# YTM32B1LE1 register map
Vendor: YTMicro; File version: 1.0
CPU: CM0PLUS r0p1, little endian, MPU, FPU, 2 interrupt priority bits
Registers are 32-bit, read-write, reset 0x0 unless marked. A register's access mark holds for its fields unless they carry their own. Offsets are from the block's base; [hi:lo] are bit positions.

## lpTMR0 — Low Power Timer
Base 0x40040000; register names take the prefix lpTMR0_
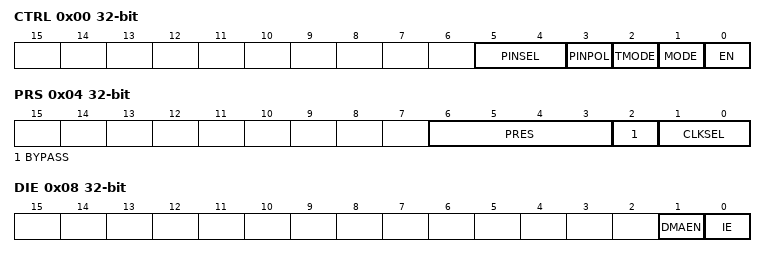
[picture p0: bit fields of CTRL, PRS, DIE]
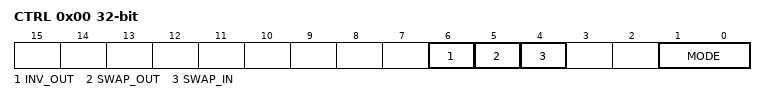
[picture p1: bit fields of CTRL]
0x00 CTRL
  [5:4] PINSEL — Configures the input source to be used in Pulse Counter mode. PINSEL must be altered only when the lpTMR is disabled.
    0=Pulse counter input 0 is selected. (It's from TMU); 2=Pulse counter input 2 is selected. (It's from lpTMR_ALT2 pad); 3=Pulse counter input 3 is selected. (It's from lpTMR_ALT3 pad)
  [3] PINPOL — Configures the polarity of the input source in Pulse Counter mode. PINPOL must be changed only when the lpTMR is disabled.
    0=Pulse Counter input source is active-high, and the CNT will increment on the rising-edge; 1=Pulse Counter input source is active-low, and the CNT will increment on the falling-edge
  [2] TMODE — When clear, TMODE configures the CNT to reset whenever CCF is set. When set, TMODE configures the CNT to reset on overflow. TMODE must be altered only when the lpTMR is disabled.
    0=CNT is reset whenever CCF is set; 1=CNT is reset on overflow
  [1] MODE — Configures the mode of the lpTMR. MODE must be altered only when the lpTMR is disabled.
    0=Time Counter mode; 1=Pulse Counter mode
  [0] EN — When EN is clear, it resets the lpTMR internal logic, including the CNT and CCF. When EN is set, the lpTMR is enabled. While writing 1 to this field, CTRL[5:1] must not be altered.
    0=lpTMR is disabled and internal logic is reset; 1=lpTMR is enabled
0x04 PRS
  [6:3] PRES — Configures the size of the Prescaler in Time Counter mode or width of the glitch filter in Pulse Counter mode. The width of the glitch filter can vary by 1 cycle due to synchronization of the pulse counter input. ewline Prescaler divides the prescaler clock by 2^(PRES+1) and glitch filter recognizes change on input pin after 2^PRES rising clock edges. ewline PRESCALE must be altered only when the lpTMR is disabled.
  [2] BYPASS — When BYPASS is set, the selected prescaler clock in Time Counter mode or selected input source in Pulse Counter mode directly clocks the CNT. When BYPASS is clear, the CNT is clocked by the output of the prescaler/glitch filter. BYPASS must be altered only when the lpTMR is disabled.
  [1:0] CLKSEL — Use to select function clock source.
    0=FIRC Clock; 1=SIRC Clock; 2=FXOSC Clock; 3=LPO_CLK
0x08 DIE
  [1] DMAEN — When DMAEN is set, the lpTMR DMA Request is generated whenever CCF is also set and the CCF is cleared when the DMA Controller is done.
    0=Timer DMA Request disabled; 1=Timer DMA Request enabled
  [0] IE — When IE is set, the lpTMR Interrupt is generated whenever CCF is also set.
    0=Timer interrupt disabled; 1=Timer interrupt enabled
0x0C STS
  [0] CCF — CCF is set when the lpTMR is enabled and the CNT equals the CMP and increments. CCF is cleared when the lpTMR is disabled or writing 1 to it.
    0=The value of CNT is not equal to CMP and increments; 1=The value of CNT is equal to CMP and increments
0x10 CMP
  [15:0] CMP — When the lpTMR is enabled and the CNT equals the value in the CMP and increments, CCF is set and the hardware trigger asserts until the next time the CNT increments. If the CMP is 0, the hardware trigger will remain asserted until the lpTMR is disabled. If the lpTMR is enabled, the CMP must be altered only when CCF is set.
0x14 LCNT wo
  [15:0] LCVAL — Write this register to latch timer counter value to CNT register, which is to avoid metastability.
0x18 CNT
  [15:0] CVAL — The CNT returns the current value of the lpTMR counter at the time this LCNT register was last written.

## CRC0 — Cyclic Redundancy Check
Base 0x40032000; register names take the prefix CRC0_
0x00 CTRL
  [6] INV_OUT — Bit-inversion for all CRC output bits.
    0=Disable the bit-inversion; 1=Enable the bit-inversion
  [5] SWAP_OUT — Swap all the valid bits (16/32-bit) for CRC output data.
    0=Disable the output bit-swap; 1=Enable the output bit-swap
  [4] SWAP_IN — Enable bit-swap in each byte for CRC input data.
    0=Disable the input bit-swap; 1=Enable the input bit-swap
  [1:0] MODE — Select CRC calculation mode.
    0=Select CRC-4 mode; 1=Select CRC-16 mode; 2=Select CRC-32 mode; 3=Select CRC-8 mode
0x04 INIT
  [31:0] SEED — This register contains the CRC initial seed value.
0x08 IN32 wo
  [31:0] DATA rw — CRC data input in 32 bits
0x0C RESULT ro
  [31:0] RESULT rw — This register contains the result of CRC calculation. In CRC-16 mode, only the low 16 bits are valid. In CRC-4 mode, only the low 4 bits are valid.
